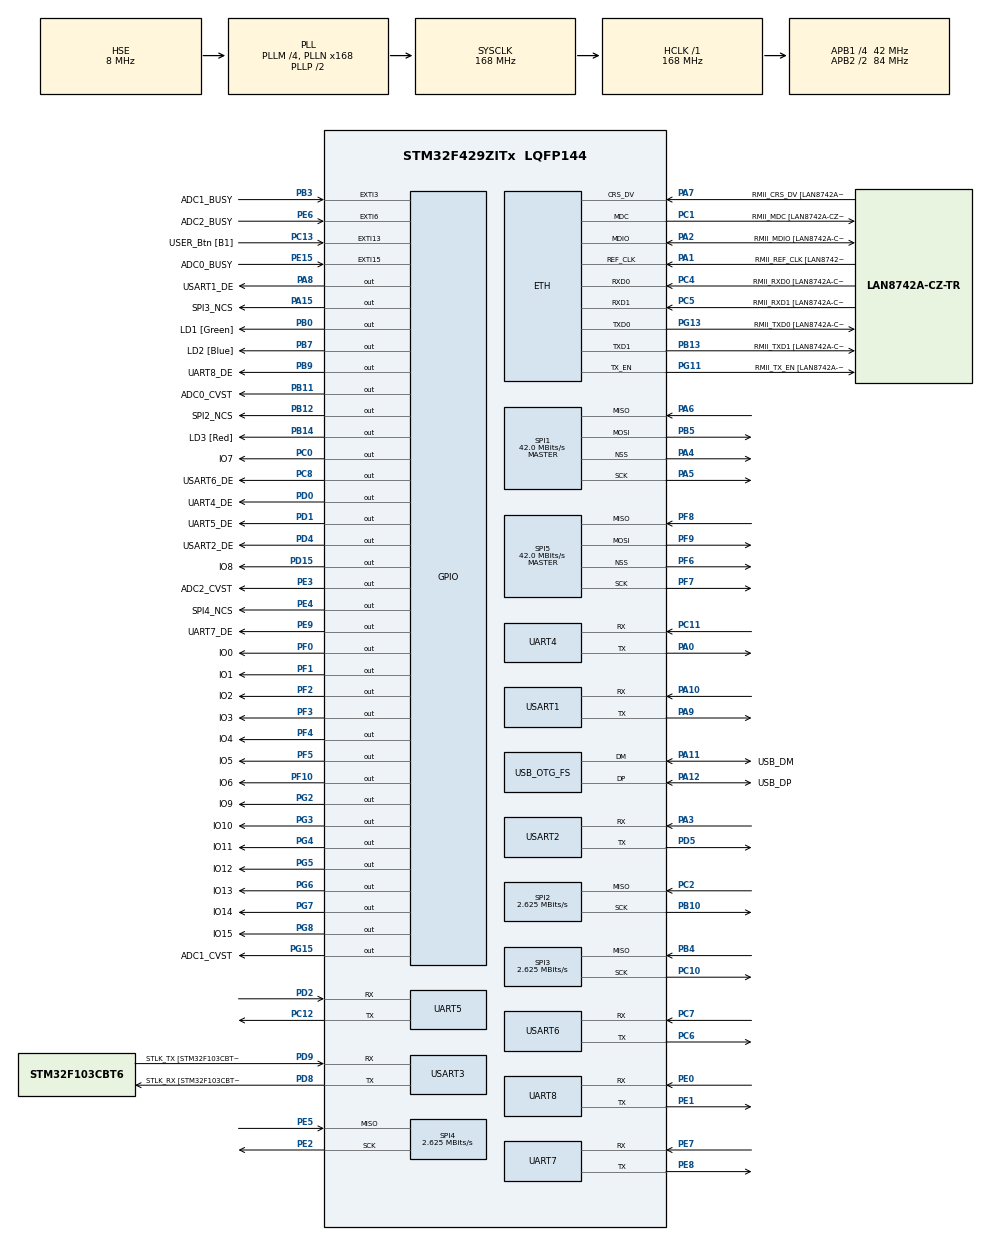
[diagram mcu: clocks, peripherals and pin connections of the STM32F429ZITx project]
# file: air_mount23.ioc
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Dma.Request0=SPI2_RX
Dma.Request1=SPI3_RX
Dma.Request2=SPI4_RX
Dma.Request3=USART3_TX
Dma.SPI2_RX.0.Direction=DMA_PERIPH_TO_MEMORY
Dma.SPI2_RX.0.FIFOMode=DMA_FIFOMODE_DISABLE
Dma.SPI2_RX.0.Instance=DMA1_Stream3
Dma.SPI2_RX.0.MemDataAlignment=DMA_MDATAALIGN_HALFWORD
Dma.SPI2_RX.0.MemInc=DMA_MINC_ENABLE
Dma.SPI2_RX.0.Mode=DMA_NORMAL
Dma.SPI2_RX.0.PeriphDataAlignment=DMA_PDATAALIGN_HALFWORD
Dma.SPI2_RX.0.PeriphInc=DMA_PINC_DISABLE
Dma.SPI2_RX.0.Priority=DMA_PRIORITY_VERY_HIGH
Dma.SPI3_RX.1.Direction=DMA_PERIPH_TO_MEMORY
Dma.SPI3_RX.1.FIFOMode=DMA_FIFOMODE_DISABLE
Dma.SPI3_RX.1.Instance=DMA1_Stream0
Dma.SPI3_RX.1.MemDataAlignment=DMA_MDATAALIGN_HALFWORD
Dma.SPI3_RX.1.MemInc=DMA_MINC_ENABLE
Dma.SPI3_RX.1.Mode=DMA_NORMAL
Dma.SPI3_RX.1.PeriphDataAlignment=DMA_PDATAALIGN_HALFWORD
Dma.SPI3_RX.1.PeriphInc=DMA_PINC_DISABLE
Dma.SPI3_RX.1.Priority=DMA_PRIORITY_VERY_HIGH
Dma.SPI4_RX.2.Direction=DMA_PERIPH_TO_MEMORY
Dma.SPI4_RX.2.FIFOMode=DMA_FIFOMODE_DISABLE
Dma.SPI4_RX.2.Instance=DMA2_Stream0
Dma.SPI4_RX.2.MemDataAlignment=DMA_MDATAALIGN_HALFWORD
Dma.SPI4_RX.2.MemInc=DMA_MINC_ENABLE
Dma.SPI4_RX.2.Mode=DMA_NORMAL
Dma.SPI4_RX.2.PeriphDataAlignment=DMA_PDATAALIGN_HALFWORD
Dma.SPI4_RX.2.PeriphInc=DMA_PINC_DISABLE
Dma.SPI4_RX.2.Priority=DMA_PRIORITY_VERY_HIGH
Dma.USART3_TX.3.Direction=DMA_MEMORY_TO_PERIPH
Dma.USART3_TX.3.FIFOMode=DMA_FIFOMODE_DISABLE
Dma.USART3_TX.3.Instance=DMA1_Stream4
Dma.USART3_TX.3.MemDataAlignment=DMA_MDATAALIGN_BYTE
Dma.USART3_TX.3.MemInc=DMA_MINC_ENABLE
Dma.USART3_TX.3.Mode=DMA_NORMAL
Dma.USART3_TX.3.PeriphDataAlignment=DMA_PDATAALIGN_BYTE
Dma.USART3_TX.3.PeriphInc=DMA_PINC_DISABLE
Dma.USART3_TX.3.Priority=DMA_PRIORITY_HIGH
ETH.MediaInterface=HAL_ETH_RMII_MODE
ETH.PHY_Name=LAN8742A_PHY_ADDRESS
ETH.PHY_Value=0
ETH.PhyAddress=0
LWIP.BSP.number=1
LWIP.GATEWAY_ADDRESS=192.168.123.001
LWIP.IP_ADDRESS=192.168.123.001
LWIP.LWIP_DHCP=0
LWIP.NETMASK_ADDRESS=255.255.255.000
LWIP.Version=v2.1.2_Cube
LWIP0.BSP.STBoard=false
LWIP0.BSP.api=BSP_COMPONENT_DRIVER
LWIP0.BSP.component=LAN8742
LWIP0.BSP.i2caddr=0
LWIP0.BSP.instance=LAN8742
LWIP0.BSP.name=Driver_PHY
LWIP0.BSP.semaphore=S_LAN8742
LWIP0.BSP.solution=LAN8742
Mcu.Family=STM32F4
Mcu.Name=STM32F429ZITx
Mcu.Package=LQFP144
NVIC.DMA1_Stream0_IRQn=true\:1\:0\:true\:false\:true\:false\:true\:true
NVIC.DMA1_Stream3_IRQn=true\:1\:0\:true\:false\:true\:false\:true\:true
NVIC.DMA1_Stream4_IRQn=true\:1\:0\:true\:false\:true\:false\:true\:true
NVIC.DMA2_Stream0_IRQn=true\:1\:0\:true\:false\:true\:false\:true\:true
NVIC.EXTI15_10_IRQn=true\:1\:0\:true\:false\:true\:true\:true\:true
NVIC.EXTI3_IRQn=true\:1\:0\:true\:false\:true\:true\:true\:true
NVIC.EXTI9_5_IRQn=true\:1\:0\:true\:false\:true\:true\:true\:true
NVIC.PVD_IRQn=true\:15\:0\:true\:false\:true\:true\:true\:true
NVIC.PriorityGroup=NVIC_PRIORITYGROUP_4
NVIC.SPI1_IRQn=true\:2\:0\:true\:false\:true\:true\:true\:true
NVIC.SPI2_IRQn=true\:2\:0\:true\:false\:true\:true\:true\:true
NVIC.SPI3_IRQn=true\:2\:0\:true\:false\:true\:true\:true\:true
NVIC.SPI4_IRQn=true\:2\:0\:true\:false\:true\:true\:true\:true
NVIC.SPI5_IRQn=true\:2\:0\:true\:false\:true\:true\:true\:true
NVIC.TIM8_UP_TIM13_IRQn=true\:1\:0\:true\:false\:true\:true\:true\:true
NVIC.UART4_IRQn=true\:1\:0\:true\:false\:true\:true\:true\:true
NVIC.UART5_IRQn=true\:1\:0\:true\:false\:true\:true\:true\:true
NVIC.UART7_IRQn=true\:1\:0\:true\:false\:true\:true\:true\:true
NVIC.UART8_IRQn=true\:1\:0\:true\:false\:true\:true\:true\:true
NVIC.USART1_IRQn=true\:1\:0\:true\:false\:true\:true\:true\:true
NVIC.USART2_IRQn=true\:1\:0\:true\:false\:true\:true\:true\:true
NVIC.USART3_IRQn=true\:2\:0\:true\:false\:true\:true\:true\:true
NVIC.USART6_IRQn=true\:1\:0\:true\:false\:true\:true\:true\:true
PA0/WKUP.Mode=Asynchronous
PA0/WKUP.Signal=UART4_TX
PA1.GPIO_Label=RMII_REF_CLK [LAN8742A-CZ-TR_REFCLK0]
PA1.Mode=RMII
PA1.Signal=ETH_REF_CLK
PA10.Mode=Asynchronous
PA10.Signal=USART1_RX
PA11.GPIO_Label=USB_DM
PA11.Mode=Device_Only
PA11.Signal=USB_OTG_FS_DM
PA12.GPIO_Label=USB_DP
PA12.Mode=Device_Only
PA12.Signal=USB_OTG_FS_DP
PA13.GPIO_Label=TMS
PA13.Mode=Serial_Wire
PA13.Signal=SYS_JTMS-SWDIO
PA14.GPIO_Label=TCK
PA14.Mode=Serial_Wire
PA14.Signal=SYS_JTCK-SWCLK
PA15.GPIO_Label=SPI3_NCS
PA15.Signal=GPIO_Output
PA2.GPIO_Label=RMII_MDIO [LAN8742A-CZ-TR_MDIO]
PA2.Mode=RMII
PA2.Signal=ETH_MDIO
PA3.Mode=Asynchronous
PA3.Signal=USART2_RX
PA4.Mode=NSS_Signal_Hard_Output
PA4.Signal=SPI1_NSS
PA5.Mode=Full_Duplex_Master
PA5.Signal=SPI1_SCK
PA6.Mode=Full_Duplex_Master
PA6.Signal=SPI1_MISO
PA7.GPIO_Label=RMII_CRS_DV [LAN8742A-CZ-TR_CRS_DV]
PA7.Mode=RMII
PA7.Signal=ETH_CRS_DV
PA8.GPIO_Label=USART1_DE
PA8.Signal=GPIO_Output
PA9.Mode=Asynchronous
PA9.Signal=USART1_TX
PB0.GPIO_Label=LD1 [Green]
PB0.Signal=GPIO_Output
PB10.Mode=RX_Only_Simplex_Unidirect_Master
PB10.Signal=SPI2_SCK
PB11.GPIO_Label=ADC0_CVST
PB11.GPIO_Speed=GPIO_SPEED_FREQ_HIGH
PB11.Signal=GPIO_Output
PB12.GPIO_Label=SPI2_NCS
PB12.Signal=GPIO_Output
PB13.GPIO_Label=RMII_TXD1 [LAN8742A-CZ-TR_TXD1]
PB13.Mode=RMII
PB13.Signal=ETH_TXD1
PB14.GPIO_Label=LD3 [Red]
PB14.Signal=GPIO_Output
PB3.GPIO_Label=ADC1_BUSY
PB3.GPIO_ModeDefaultEXTI=GPIO_MODE_IT_FALLING
PB3.GPIO_PuPd=GPIO_PULLUP
PB3.Signal=GPXTI3
PB4.Mode=RX_Only_Simplex_Unidirect_Master
PB4.Signal=SPI3_MISO
PB5.Mode=Full_Duplex_Master
PB5.Signal=SPI1_MOSI
PB7.GPIO_Label=LD2 [Blue]
PB7.Signal=GPIO_Output
PB9.GPIO_Label=UART8_DE
PB9.Signal=GPIO_Output
PC0.GPIO_Label=IO7
PC0.Signal=GPIO_Output
PC1.GPIO_Label=RMII_MDC [LAN8742A-CZ-TR_MDC]
PC1.Mode=RMII
PC1.Signal=ETH_MDC
PC10.Mode=RX_Only_Simplex_Unidirect_Master
PC10.Signal=SPI3_SCK
PC11.Mode=Asynchronous
PC11.Signal=UART4_RX
PC12.Mode=Asynchronous
PC12.Signal=UART5_TX
PC13.GPIO_Label=USER_Btn [B1]
PC13.Signal=GPXTI13
PC14/OSC32_IN.Signal=RCC_OSC32_IN
PC15/OSC32_OUT.Signal=RCC_OSC32_OUT
PC2.Mode=RX_Only_Simplex_Unidirect_Master
PC2.Signal=SPI2_MISO
PC4.GPIO_Label=RMII_RXD0 [LAN8742A-CZ-TR_RXD0]
PC4.Mode=RMII
PC4.Signal=ETH_RXD0
PC5.GPIO_Label=RMII_RXD1 [LAN8742A-CZ-TR_RXD1]
PC5.Mode=RMII
PC5.Signal=ETH_RXD1
PC6.Mode=Asynchronous
PC6.Signal=USART6_TX
PC7.Mode=Asynchronous
PC7.Signal=USART6_RX
PC8.GPIO_Label=USART6_DE
PC8.Signal=GPIO_Output
PD0.GPIO_Label=UART4_DE
PD0.Signal=GPIO_Output
PD1.GPIO_Label=UART5_DE
PD1.Signal=GPIO_Output
PD15.GPIO_Label=IO8
PD15.Signal=GPIO_Output
PD2.Mode=Asynchronous
PD2.Signal=UART5_RX
PD4.GPIO_Label=USART2_DE
PD4.Signal=GPIO_Output
PD5.Mode=Asynchronous
PD5.Signal=USART2_TX
PD8.GPIO_Label=STLK_RX [STM32F103CBT6_PA3]
PD8.Mode=Asynchronous
PD8.Signal=USART3_TX
PD9.GPIO_Label=STLK_TX [STM32F103CBT6_PA2]
PD9.Mode=Asynchronous
PD9.Signal=USART3_RX
PE0.Mode=Asynchronous
PE0.Signal=UART8_RX
PE1.Mode=Asynchronous
PE1.Signal=UART8_TX
PE15.GPIO_Label=ADC0_BUSY
PE15.GPIO_ModeDefaultEXTI=GPIO_MODE_IT_FALLING
PE15.GPIO_PuPd=GPIO_PULLUP
PE15.Signal=GPXTI15
PE2.Mode=RX_Only_Simplex_Unidirect_Master
PE2.Signal=SPI4_SCK
PE3.GPIO_Label=ADC2_CVST
PE3.GPIO_Speed=GPIO_SPEED_FREQ_HIGH
PE3.Signal=GPIO_Output
PE4.GPIO_Label=SPI4_NCS
PE4.Signal=GPIO_Output
PE5.Mode=RX_Only_Simplex_Unidirect_Master
PE5.Signal=SPI4_MISO
PE6.GPIO_Label=ADC2_BUSY
PE6.GPIO_ModeDefaultEXTI=GPIO_MODE_IT_FALLING
PE6.GPIO_PuPd=GPIO_PULLUP
PE6.Signal=GPXTI6
PE7.Mode=Asynchronous
PE7.Signal=UART7_RX
PE8.Mode=Asynchronous
PE8.Signal=UART7_TX
PE9.GPIO_Label=UART7_DE
PE9.Signal=GPIO_Output
PF0.GPIO_Label=IO0
PF0.Signal=GPIO_Output
PF1.GPIO_Label=IO1
PF1.Signal=GPIO_Output
PF10.GPIO_Label=IO6
PF10.Signal=GPIO_Output
PF2.GPIO_Label=IO2
PF2.Signal=GPIO_Output
PF3.GPIO_Label=IO3
PF3.Signal=GPIO_Output
PF4.GPIO_Label=IO4
PF4.Signal=GPIO_Output
PF5.GPIO_Label=IO5
PF5.Signal=GPIO_Output
PF6.Mode=NSS_Signal_Hard_Output
PF6.Signal=SPI5_NSS
PF7.Mode=Full_Duplex_Master
PF7.Signal=SPI5_SCK
PF8.Mode=Full_Duplex_Master
PF8.Signal=SPI5_MISO
PF9.Mode=Full_Duplex_Master
PF9.Signal=SPI5_MOSI
PG11.GPIO_Label=RMII_TX_EN [LAN8742A-CZ-TR_TXEN]
PG11.Mode=RMII
PG11.Signal=ETH_TX_EN
PG13.GPIO_Label=RMII_TXD0 [LAN8742A-CZ-TR_TXD0]
PG13.Mode=RMII
PG13.Signal=ETH_TXD0
PG15.GPIO_Label=ADC1_CVST
PG15.GPIO_Speed=GPIO_SPEED_FREQ_HIGH
PG15.PinState=GPIO_PIN_RESET
PG15.Signal=GPIO_Output
PG2.GPIO_Label=IO9
PG2.Signal=GPIO_Output
PG3.GPIO_Label=IO10
PG3.Signal=GPIO_Output
PG4.GPIO_Label=IO11
PG4.Signal=GPIO_Output
PG5.GPIO_Label=IO12
PG5.Signal=GPIO_Output
PG6.GPIO_Label=IO13
PG6.Signal=GPIO_Output
PG7.GPIO_Label=IO14
PG7.Signal=GPIO_Output
PG8.GPIO_Label=IO15
PG8.Signal=GPIO_Output
PH0/OSC_IN.GPIO_Label=MCO [STM32F103CBT6_PA8]
PH0/OSC_IN.Mode=HSE-External-Oscillator
PH0/OSC_IN.Signal=RCC_OSC_IN
PH1/OSC_OUT.Mode=HSE-External-Oscillator
PH1/OSC_OUT.Signal=RCC_OSC_OUT
ProjectManager.HeapSize=0x2000
ProjectManager.StackSize=0x2000
ProjectManager.TargetToolchain=STM32CubeIDE
RCC.48MHZClocksFreq_Value=48000000
RCC.AHBFreq_Value=168000000
RCC.APB1CLKDivider=RCC_HCLK_DIV4
RCC.APB1Freq_Value=42000000
RCC.APB1TimFreq_Value=84000000
RCC.APB2CLKDivider=RCC_HCLK_DIV2
RCC.APB2Freq_Value=84000000
RCC.APB2TimCLKDivider=2
RCC.APB2TimFreq_Value=168000000
RCC.CortexFreq_Value=168000000
RCC.HCLKFreq_Value=168000000
RCC.HSE_VALUE=8000000
RCC.HSI_VALUE=16000000
RCC.LSE_VALUE=32768
RCC.PLLM=4
RCC.PLLMUL=RCC_PLL_MUL9
RCC.PLLN=168
RCC.PLLQ=7
RCC.PRESCALERUSB=RCC_USBCLKSOURCE_PLL_DIV1_5
RCC.SYSCLKFreq_VALUE=168000000
RCC.SYSCLKSource=RCC_SYSCLKSOURCE_PLLCLK
RCC.SYSCLKSourceVirtual=RCC_SYSCLKSOURCE_PLLCLK
RCC.USBFreq_Value=48000000
RCC.VCOOutputFreq_Value=336000000
SPI1.CLKPhase=SPI_PHASE_2EDGE
SPI1.CalculateBaudRate=42.0 MBits/s
SPI1.Direction=SPI_DIRECTION_2LINES
SPI1.Mode=SPI_MODE_MASTER
SPI1.VirtualNSS=VM_NSSHARD
SPI1.VirtualType=VM_MASTER
SPI2.BaudRatePrescaler=SPI_BAUDRATEPRESCALER_16
SPI2.CLKPhase=SPI_PHASE_2EDGE
SPI2.CLKPolarity=SPI_POLARITY_HIGH
SPI2.CalculateBaudRate=2.625 MBits/s
SPI2.DataSize=SPI_DATASIZE_16BIT
SPI2.Direction=SPI_DIRECTION_2LINES_RXONLY
SPI2.Mode=SPI_MODE_MASTER
SPI2.VirtualType=VM_MASTER
SPI3.BaudRatePrescaler=SPI_BAUDRATEPRESCALER_16
SPI3.CLKPhase=SPI_PHASE_2EDGE
SPI3.CLKPolarity=SPI_POLARITY_HIGH
SPI3.CalculateBaudRate=2.625 MBits/s
SPI3.DataSize=SPI_DATASIZE_16BIT
SPI3.Direction=SPI_DIRECTION_2LINES_RXONLY
SPI3.Mode=SPI_MODE_MASTER
SPI3.VirtualType=VM_MASTER
SPI4.BaudRatePrescaler=SPI_BAUDRATEPRESCALER_32
SPI4.CLKPhase=SPI_PHASE_2EDGE
SPI4.CLKPolarity=SPI_POLARITY_HIGH
SPI4.CalculateBaudRate=2.625 MBits/s
SPI4.DataSize=SPI_DATASIZE_16BIT
SPI4.Direction=SPI_DIRECTION_2LINES_RXONLY
SPI4.Mode=SPI_MODE_MASTER
SPI4.VirtualType=VM_MASTER
SPI5.CalculateBaudRate=42.0 MBits/s
SPI5.Direction=SPI_DIRECTION_2LINES
SPI5.Mode=SPI_MODE_MASTER
SPI5.VirtualNSS=VM_NSSHARD
SPI5.VirtualType=VM_MASTER
TIM13.AutoReloadPreload=TIM_AUTORELOAD_PRELOAD_ENABLE
TIM13.Period=1999
TIM13.Prescaler=83
TIM2.Prescaler=83
UART4.VirtualMode=Asynchronous
UART5.VirtualMode=Asynchronous
UART7.VirtualMode=Asynchronous
UART8.VirtualMode=Asynchronous
USART1.VirtualMode=VM_ASYNC
USART2.VirtualMode=VM_ASYNC
USART3.VirtualMode=VM_ASYNC
USART6.VirtualMode=VM_ASYNC
USB_OTG_FS.VirtualMode=Device_Only
VP_LWIP_VS_Enabled.Mode=Enabled
VP_TIM13_VS_ClockSourceINT.Mode=Enable_Timer
VP_TIM2_VS_ClockSourceINT.Mode=Internal
board=NUCLEO-F429ZI

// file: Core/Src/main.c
/* USER CODE BEGIN Header */
/**
  ******************************************************************************
  * @file           : main.c
  * @brief          : Main program body
  ******************************************************************************
  * @attention
  *
  * Copyright (c) 2023 STMicroelectronics.
  * All rights reserved.
  *
  * This software is licensed under terms that can be found in the LICENSE file
  * in the root directory of this software component.
  * If no LICENSE file comes with this software, it is provided AS-IS.
  *
  ******************************************************************************
  */
/* USER CODE END Header */
#include "main.h"
#include "dma.h"
#include "lwip.h"
#include "spi.h"
#include "tim.h"
#include "usart.h"
#include "usb_otg.h"
#include "gpio.h"

void SystemClock_Config(void);

int main(void)
{

  /* MCU Configuration--------------------------------------------------------*/

  /* Reset of all peripherals, Initializes the Flash interface and the Systick. */
  HAL_Init();

  /* Configure the system clock */
  SystemClock_Config();

  /* Initialize all configured peripherals */
  MX_GPIO_Init();
  MX_DMA_Init();
  MX_USART3_UART_Init();
  MX_USART1_UART_Init();
  MX_UART8_Init();
  MX_UART7_Init();
  MX_USB_OTG_FS_PCD_Init();
  MX_UART5_Init();
  MX_UART4_Init();
  MX_USART6_UART_Init();
  MX_SPI5_Init();
  MX_SPI4_Init();
  MX_SPI3_Init();
  MX_SPI2_Init();
  MX_SPI1_Init();
  MX_TIM2_Init();
  MX_USART2_UART_Init();
  MX_LWIP_Init();
  MX_TIM13_Init();
  /* USER CODE BEGIN 2 */
  extern void avis();
  avis();
  /* USER CODE END 2 */

  /* Infinite loop */
  while (1)
  {

  }
}

void SystemClock_Config(void)
{
  RCC_OscInitTypeDef RCC_OscInitStruct = {0};
  RCC_ClkInitTypeDef RCC_ClkInitStruct = {0};

  /** Configure the main internal regulator output voltage
  */
  __HAL_RCC_PWR_CLK_ENABLE();
  __HAL_PWR_VOLTAGESCALING_CONFIG(PWR_REGULATOR_VOLTAGE_SCALE1);

  /** Initializes the RCC Oscillators according to the specified parameters
  * in the RCC_OscInitTypeDef structure.
  */
  RCC_OscInitStruct.OscillatorType = RCC_OSCILLATORTYPE_HSE;
  RCC_OscInitStruct.HSEState = RCC_HSE_ON;
  RCC_OscInitStruct.PLL.PLLState = RCC_PLL_ON;
  RCC_OscInitStruct.PLL.PLLSource = RCC_PLLSOURCE_HSE;
  RCC_OscInitStruct.PLL.PLLM = 4;
  RCC_OscInitStruct.PLL.PLLN = 168;
  RCC_OscInitStruct.PLL.PLLP = RCC_PLLP_DIV2;
  RCC_OscInitStruct.PLL.PLLQ = 7;
  if (HAL_RCC_OscConfig(&RCC_OscInitStruct) != HAL_OK)
  {
    Error_Handler();
  }

  /** Initializes the CPU, AHB and APB buses clocks
  */
  RCC_ClkInitStruct.ClockType = RCC_CLOCKTYPE_HCLK|RCC_CLOCKTYPE_SYSCLK
                              |RCC_CLOCKTYPE_PCLK1|RCC_CLOCKTYPE_PCLK2;
  RCC_ClkInitStruct.SYSCLKSource = RCC_SYSCLKSOURCE_PLLCLK;
  RCC_ClkInitStruct.AHBCLKDivider = RCC_SYSCLK_DIV1;
  RCC_ClkInitStruct.APB1CLKDivider = RCC_HCLK_DIV4;
  RCC_ClkInitStruct.APB2CLKDivider = RCC_HCLK_DIV2;

  if (HAL_RCC_ClockConfig(&RCC_ClkInitStruct, FLASH_LATENCY_5) != HAL_OK)
  {
    Error_Handler();
  }
}

void Error_Handler(void)
{
  __disable_irq();
  while (1)
  {
  }
}
